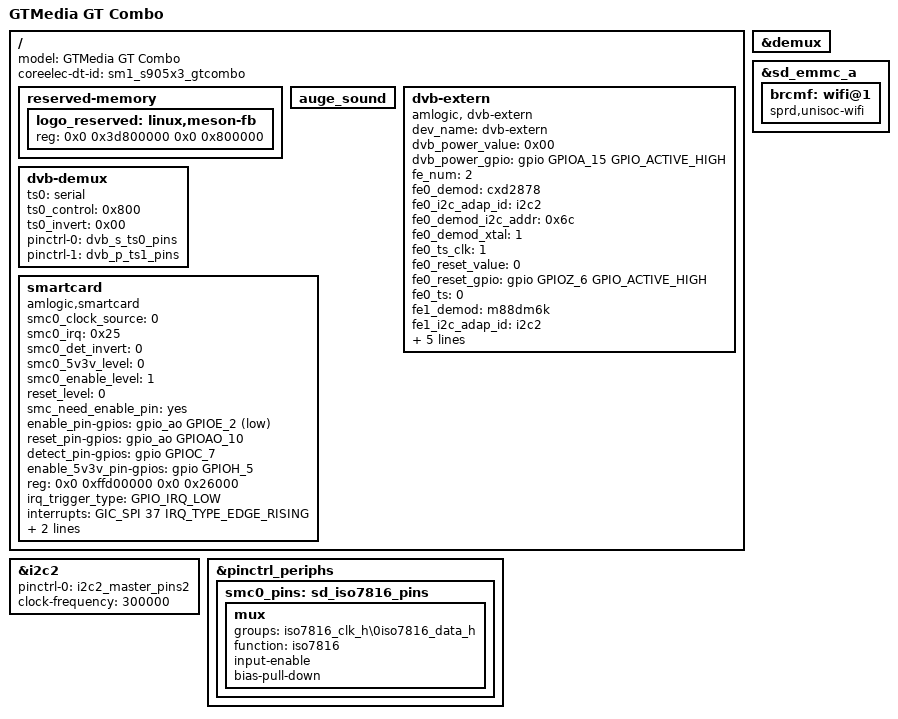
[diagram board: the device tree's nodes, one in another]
#include "sm1_s905x3_2g.dts"

/{
	model = "GTMedia GT Combo";
	coreelec-dt-id = "sm1_s905x3_gtcombo";

	reserved-memory {
		logo_reserved:linux,meson-fb {
			reg = <0x0 0x3d800000 0x0 0x800000>;
		};
	};

	//GPIOAO_2 collides with VFD
	auge_sound {
		/delete-property/ avout_mute-gpios;
	};
	/delete-node/ sdcard-1v8_3v3;

	dvb-extern {
		compatible = "amlogic, dvb-extern";
		dev_name = "dvb-extern";
		status = "okay";

		dvb_power_value = <0x00>;
		dvb_power_gpio = <&gpio GPIOA_15 GPIO_ACTIVE_HIGH>;
		fe_num = <2>;

		fe0_demod = "cxd2878";
		fe0_i2c_adap_id = <&i2c2>;
		fe0_demod_i2c_addr = <0x6c>;
		fe0_demod_xtal = <1>;
		fe0_ts_clk = <1>;
		fe0_reset_value = <0>;
		fe0_reset_gpio = <&gpio GPIOZ_6 GPIO_ACTIVE_HIGH>;
		fe0_ts = <0>;

		fe1_demod = "m88dm6k";
		fe1_i2c_adap_id = <&i2c2>;
		fe1_demod_i2c_addr = <0x69>;
		fe1_ts_out_mode = <1>;
		fe1_reset_value = <0>;
		fe1_reset_gpio = <&gpio GPIOZ_1 GPIO_ACTIVE_HIGH>;
		fe1_ts = <1>;
	};
	
	dvb-demux {
		status = "okay";

		ts0 = "serial";
		ts0_control = <0x800>;
		ts0_invert = <0x00>;
		pinctrl-names = "s_ts0", "p_ts1";
		pinctrl-0 = <&dvb_s_ts0_pins>;
		pinctrl-1 = <&dvb_p_ts1_pins>;
	};

	smartcard {
		compatible = "amlogic,smartcard";
		status = "okay";

		smc0_clock_source = <0>;
		smc0_irq = <0x25>;
		smc0_det_invert = <0>;
		smc0_5v3v_level = <0>;
		smc0_enable_level = <1>;
		reset_level = <0>;
		smc_need_enable_pin = "yes";
		enable_pin-gpios = <&gpio_ao GPIOE_2 GPIO_ACTIVE_LOW>;
		reset_pin-gpios = <&gpio_ao GPIOAO_10 GPIO_ACTIVE_HIGH>;
		detect_pin-gpios = <&gpio GPIOC_7 GPIO_ACTIVE_HIGH>;
		enable_5v3v_pin-gpios = <&gpio GPIOH_5 GPIO_ACTIVE_HIGH>;

		reg = <0x0 0xffd00000 0x0 0x26000>;
		irq_trigger_type = "GPIO_IRQ_LOW";
		interrupts = <GIC_SPI 37 IRQ_TYPE_EDGE_RISING>;
		interrupt-names = "smc0_irq";
		clocks = <&clkc CLKID_SD>;
		clock-names = "smartcard";
		pinctrl-names = "default";
		pinctrl-0 = <&smc0_pins>;
	};
};

&i2c2 {
	status = "okay";
	pinctrl-names = "default";
	pinctrl-0 = <&i2c2_master_pins2>;
	clock-frequency = <300000>;
};

&demux {
	status = "okay";
};

&sd_emmc_a {
	brcmf: wifi@1 {
		compatible = "sprd,unisoc-wifi";
	};
};

&pinctrl_periphs {
	smc0_pins: sd_iso7816_pins {
		mux {
			groups = "iso7816_clk_h\0iso7816_data_h";
			function = "iso7816";
			input-enable;
			bias-pull-down;
		};
	};
};
